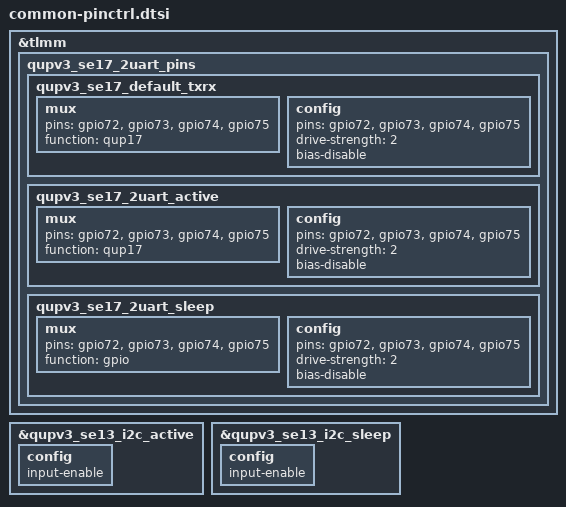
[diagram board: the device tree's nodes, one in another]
/*
 * Common dtsi pinctrl changes for Asus lahaina platform
 */

&tlmm {
	qupv3_se17_2uart_pins: qupv3_se17_2uart_pins {
		qupv3_se17_default_txrx: qupv3_se17_default_txrx {
			mux {
				pins = "gpio72", "gpio73",
						"gpio74", "gpio75";
				function = "qup17";
			};

			config {
				pins = "gpio72", "gpio73",
						"gpio74", "gpio75";
				drive-strength = <2>;
				bias-disable;
			};
		};

		qupv3_se17_2uart_active: qupv3_se17_2uart_active {
			mux {
				pins = "gpio72", "gpio73",
						"gpio74", "gpio75";
				function = "qup17";
			};

			config {
				pins = "gpio72", "gpio73",
						"gpio74", "gpio75";
				drive-strength = <2>;
				bias-disable;
			};
		};

		qupv3_se17_2uart_sleep: qupv3_se17_2uart_sleep {
			mux {
				pins = "gpio72", "gpio73",
						"gpio74", "gpio75";
				function = "gpio";
			};

			config {
				pins = "gpio72", "gpio73",
						"gpio74", "gpio75";
				drive-strength = <2>;
				bias-disable;
			};
		};
	};
};

&qupv3_se13_i2c_active {
	config {
		input-enable;
	};
};

&qupv3_se13_i2c_sleep {
	config {
		input-enable;
	};
};
